AUTOSAR XML (schema 00052)
package /Components
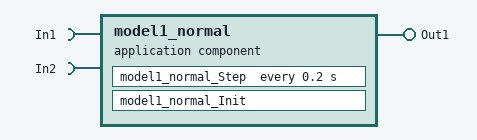
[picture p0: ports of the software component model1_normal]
  application sw component type model1_normal
    require port In1: nonqueued-receiver-com-spec{data-element=In1, init-value=0}, required-interface=In1
    require port In2: nonqueued-receiver-com-spec{data-element=In2, init-value=0}, required-interface=In2
    provide port Out1: nonqueued-sender-com-spec{data-element=Out1, init-value=0}, provided-interface=Out1
    behavior model1_normal_IB: handle-termination-and-restart=NO-SUPPORT
      timing event Event_model1_normal_Step: start-on-event=model1_normal_Step, period=0.2
      runnable model1_normal_Init
      runnable model1_normal_Step
        data-read-access:
          access IN_In1_In1: accessed-variable=In1.In1
          access IN_In2_In2: accessed-variable=In2.In2
        data-write-access:
          access OUT_Out1_Out1: accessed-variable=Out1.Out1
